# ISD9100_v3 register map
File version: 1.0
Registers are 32-bit, read-write, reset 0x0 unless marked. A register's access mark holds for its fields unless they carry their own. Offsets are from the block's base; [hi:lo] are bit positions.

## SYSINFO — SYSINFO Register Map
Base 0xE000ED00
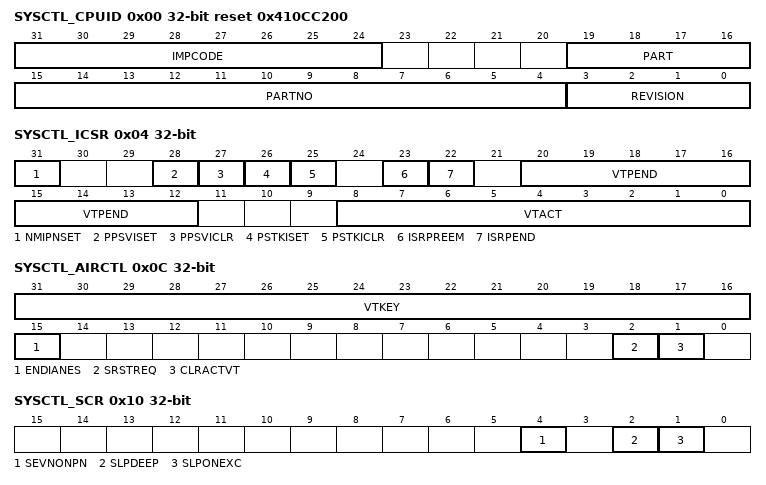
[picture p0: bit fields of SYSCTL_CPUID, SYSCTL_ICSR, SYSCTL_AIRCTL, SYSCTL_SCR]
0x00 SYSCTL_CPUID ro reset 0x410CC200 — CPUID Base Register
  [31:24] IMPCODE — Implementer Code Assigned By ARM. ARM aaa 0x41.
  [19:16] PART — ARMv6-M Parts. Reads as 0xC for ARMv6-M parts
  [15:4] PARTNO — Part Number. Reads as 0xC20.
  [3:0] REVISION — Revision. Reads as 0x0
0x04 SYSCTL_ICSR — Interrupt Control State Register
  [31] NMIPNSET — NMI Pending Set Control. Setting this bit will activate an NMI. Since NMI is the highest priority exception, it will activate as soon as it is registered. Reads back with current state (1 if Pending, 0 if not).
  [28] PPSVISET — Set A Pending PendSV Interrupt. This is normally used to request a context switch. Reads back with current state (1 if Pending, 0 if not).
  [27] PPSVICLR — Clear A Pending PendSV Interrupt. Write 1 to clear a pending PendSV interrupt.
  [26] PSTKISET — Set A pending SysTick. Reads back with current state (1 if Pending, 0 if not).
  [25] PSTKICLR — Clear A pending SysTick. Write 1 to clear a pending SysTick.
  [23] ISRPREEM — ISR Preemptive. If set, a pending exception will be serviced on exit from the debug halt state.
  [22] ISRPEND — ISR Pending. Indicates if an external configurable (NVIC generated) interrupt is pending.
  [20:12] VTPEND — Vector Pending. Indicates the exception number for the highest priority pending exception. The pending state includes the effect of memory-mapped enable and mask registers. It does not include the PRIMASK special-purpose register qualifier. A value of zero indicates no pending exceptions.
  [8:0] VTACT — Vector Active. 0: Thread mode. Value > 1: the exception number for the current executing exception.
0x0C SYSCTL_AIRCTL — Application Interrupt and Reset Control Register
  [31:16] VTKEY — Vector Key. The value 0x05FA must be written to this register, otherwise a write to register is UNPREDICTABLE.
  [15] ENDIANES — Endianess. Read Only. Reads 0 indicating little endian machine.
  [2] SRSTREQ — System Reset Request. Writing 1 to this bit asserts a signal to request a reset by the external system.
    0=do not request a reset; 1=request reset
  [1] CLRACTVT — Clear All Active Vector. Clears all active state information for fixed and configurable exceptions. The effect of writing a 1 to this bit if the processor is not halted in Debug, is UNPREDICTABLE.
    0=do not clear state information; 1=clear state information
0x10 SYSCTL_SCR — System Control Register
  [4] SEVNONPN — Send Event On Pending Bit. When enabled, interrupt transitions from Inactive to Pending are included in the list of wakeup events for the WFE instruction. When an event or interrupt enters pending state, the event signal wakes up the processor from WFE. If the processor is not waiting for an event, the event is registered and affects the next WFE. The processor also wakes up on execution of an SEV instruction.
    0=only enabled interrupts or events can wake-up the processor, disabled interrupts are excluded; 1=enabled events and all interrupts, including disabled interrupts, can wake-up the processor
  [2] SLPDEEP — Sleep Deep Control. Controls whether the processor uses sleep or deep sleep as its low power mode: The SLPDEEP flag is also used in conjunction with CLK_PWRCTL register to enter deeper power-down states than purely core sleep states.
    0=sleep; 1=deep sleep
  [1] SLPONEXC — Sleep On Exception. When set to 1, the core can enter a sleep state on an exception return to Thread mode. This is the mode and exception level entered at reset, the base level of execution. Setting this bit to 1 enables an interrupt driven application to avoid returning to an empty main application.
0x1C SYSCTL_SHPR2 — System Handler Priority Register 2
  [31:30] PRI11 — Priority Of System Handler 11 - SVCall "0" denotes the highest priority and "3" denotes lowest priority
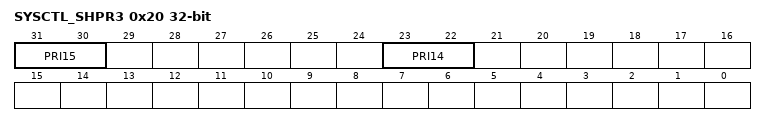
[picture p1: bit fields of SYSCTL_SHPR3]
0x20 SYSCTL_SHPR3 — System Handler Priority Register 3
  [31:30] PRI15 — Priority Of System Handler 15 - SysTick "0" denotes the highest priority and "3" denotes lowest priority
  [23:22] PRI14 — Priority Of System Handler 14 - PendSV "0" denotes the highest priority and "3" denotes lowest priority
